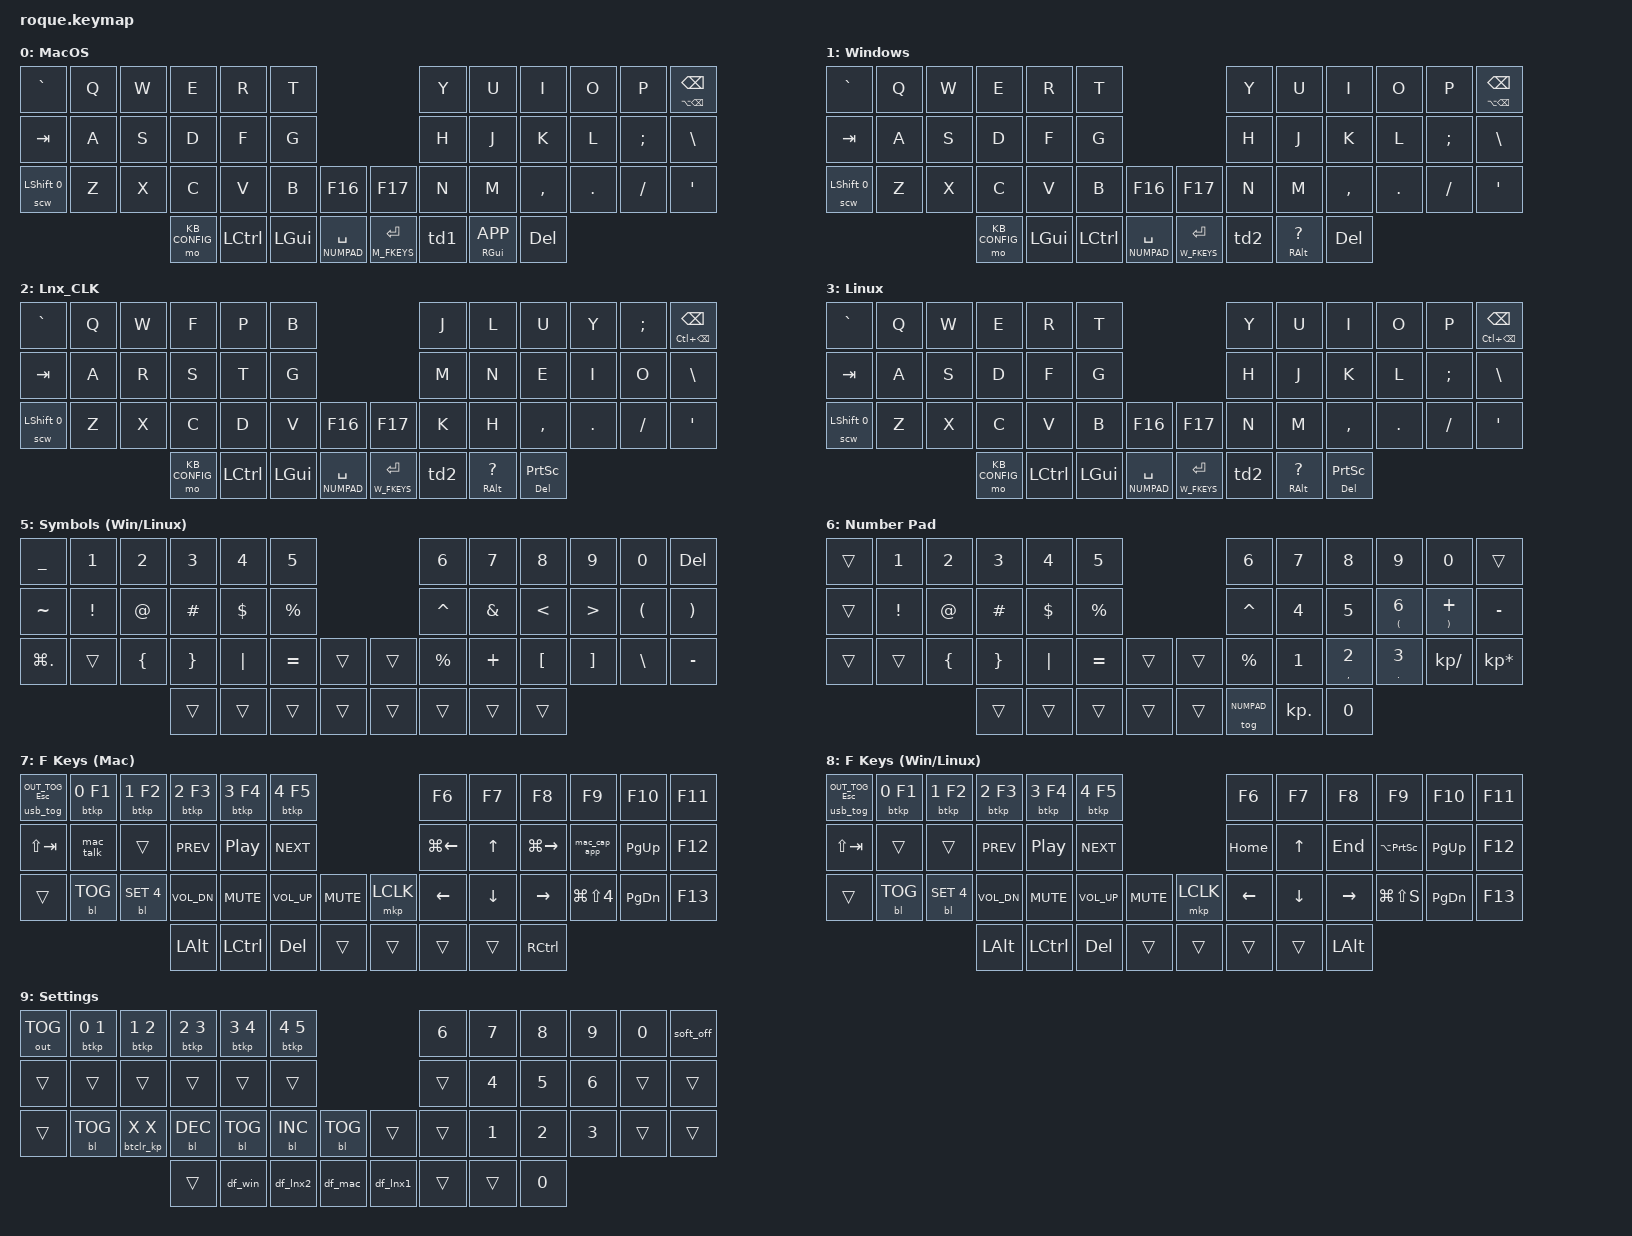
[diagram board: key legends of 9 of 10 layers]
/*
 * Copyright (c) 2023 The ZMK Contributors
 *
 * SPDX-License-Identifier: MIT
 */

#include <behaviors.dtsi>
#include <dt-bindings/zmk/keys.h>
#include <dt-bindings/zmk/bt.h>
#include <dt-bindings/zmk/outputs.h>
#include <dt-bindings/zmk/backlight.h>
#include "elpekenin/behaviors.dtsi"

#define ZMK_POINTING_DEFAULT_SCRL_VAL 100
#include <dt-bindings/zmk/pointing.h>

// Helpful macros borrowed from AndrewMSHowe
#define ___ &trans

// Layer numbers for use by the keymap & macros
#define MACOS     0
#define WINDOWS   1
#define LINUX_CLK 2
#define LINUX     3
#define M_SYMBOLS 4
#define W_SYMBOLS 5
#define NUMPAD    6
#define M_FKEYS   7
#define W_FKEYS   8
#define KB_CONFIG 9

#include "keymap_behaviors.dtsi"
#include "keymap_macros.dtsi"

/ {
    keymap {
        compatible = "zmk,keymap";

        default_layer {
            display-name = "MacOS";
            sensor-bindings = <&inc_dec_kp UP DOWN &inc_dec_kp LEFT RIGHT>;
            bindings = <
// ╭─────────────────┬─────────────┬────────────┬────────────────────┬─────────────────┬────────────╮                                         ╭───────────────┬─────────────────────┬─────────────────┬───────────────┬─────────────────┬───────────────────────╮
       &kp  GRAVE       &kp Q          &kp W        &kp E                 &kp R           &kp T   /*|                                         |*/   &kp Y          &kp U                &kp I               &kp O           &kp P             &mt LA(BSPC) BSPC
       &kp  TAB         &kp A          &kp S        &kp D                 &kp F           &kp G   /*├──────────────────╮╭─────────────────────┤*/   &kp H          &kp J                &kp K               &kp L           &kp SEMI          &kp BSLH
       &scw LSHIFT 0    &kp Z          &kp X        &kp C                 &kp V           &kp B       &kp F16             &kp F17                   &kp N          &kp M                &kp COMMA           &kp DOT         &kp FSLH           &kp SQT
/* ╰─────────────────┴─────────────┴────────────┤*/ &mo KB_CONFIG         &kp LCTRL       &kp LGUI    &lt NUMPAD SPACE    &lt M_FKEYS ENTER         &td1           &mt RGUI K_APP       &kp DEL     //├───────────────┴─────────────────┴───────────────────────╯
//                                              ╰────────────────────┴─────────────────┴────────────┴──────────────────╯╰─────────────────────┴───────────────┴─────────────────────┴─────────────────╯
            >;
        };

        windows_default_layer {
            display-name = "Windows";
            sensor-bindings = <&inc_dec_kp UP DOWN &inc_dec_kp LEFT RIGHT>;
            bindings = <
// ╭─────────────────┬─────────────┬────────────┬────────────────────┬─────────────────┬────────────╮                                         ╭───────────────┬─────────────────────┬─────────────────┬───────────────┬───────────────┬─────────────────────────╮
       &kp  GRAVE       &kp Q          &kp W        &kp E                 &kp R           &kp T   /*|                                         |*/   &kp Y          &kp U                &kp I               &kp O           &kp P             &mt LA(BSPC) BSPC
       &kp  TAB         &kp A          &kp S        &kp D                 &kp F           &kp G   /*├─────────────────╮╭──────────────────────┤*/   &kp H          &kp J                &kp K               &kp L           &kp SEMI          &kp BSLH
       &scw LSHIFT 0    &kp Z          &kp X        &kp C                 &kp V           &kp B       &kp F16             &kp F17                   &kp N          &kp M                &kp COMMA           &kp DOT         &kp FSLH          &kp APOS
/* ╰─────────────────┴─────────────┴────────────┤*/ &mo KB_CONFIG         &kp LGUI        &kp LCTRL   &lt NUMPAD SPACE    &lt W_FKEYS ENTER         &td2           &mt RALT QMARK       &kp DEL        //├───────────────┴───────────────┴─────────────────────────╯
//                                              ╰─────────────────────┴─────────────────┴───────────┴─────────────────╯╰─────────────────────┴────────────────┴─────────────────────┴─────────────────╯
            >;
        };

        Linux_CLK_default_layer {
            display-name = "Lnx_CLK";
            sensor-bindings = <&inc_dec_kp UP DOWN &inc_dec_kp LEFT RIGHT>;
            bindings = <
// ╭─────────────────┬─────────────┬────────────┬────────────────────┬─────────────────┬────────────╮                                         ╭───────────────┬─────────────────────┬─────────────────┬───────────────┬───────────────┬─────────────────────────╮
       &kp  GRAVE       &kp Q          &kp W        &kp F                 &kp P           &kp B   /*|                                         |*/   &kp J          &kp L                &kp U               &kp Y           &kp SEMI          &mt LC(BSPC) BSPC
       &kp  TAB         &kp A          &kp R        &kp S                 &kp T           &kp G   /*├──────────────────╮╭─────────────────────┤*/   &kp M          &kp N                &kp E               &kp I           &kp O             &kp BSLH
       &scw LSHIFT 0    &kp Z          &kp X        &kp C                 &kp D           &kp V       &kp F16             &kp F17                   &kp K          &kp H                &kp COMMA           &kp DOT         &kp FSLH          &kp APOS
/* ╰─────────────────┴─────────────┴────────────┤*/ &mo KB_CONFIG         &kp LCTRL       &kp LGUI    &lt NUMPAD SPACE    &lt W_FKEYS ENTER         &td2           &mt RALT QMARK       &mt DEL PSCRN //├───────────────┴───────────────┴─────────────────────────╯
//                                              ╰────────────────────┴─────────────────┴────────────┴──────────────────╯╰─────────────────────┴───────────────┴─────────────────────┴───────────────────╯
            >;
        };

        Linux_default_layer {
            display-name = "Linux";
            sensor-bindings = <&inc_dec_kp UP DOWN &inc_dec_kp LEFT RIGHT>;
            bindings = <
// ╭─────────────────┬─────────────┬────────────┬────────────────────┬─────────────────┬────────────╮                                         ╭───────────────┬─────────────────────┬─────────────────┬───────────────┬───────────────┬─────────────────────────╮
       &kp  GRAVE       &kp Q          &kp W        &kp E                 &kp R           &kp T   /*|                                         |*/   &kp Y          &kp U                &kp I               &kp O           &kp P             &mt LC(BSPC) BSPC
       &kp  TAB         &kp A          &kp S        &kp D                 &kp F           &kp G   /*├──────────────────╮╭─────────────────────┤*/   &kp H          &kp J                &kp K               &kp L           &kp SEMI          &kp BSLH
       &scw LSHIFT 0    &kp Z          &kp X        &kp C                 &kp V           &kp B       &kp F16             &kp F17                   &kp N          &kp M                &kp COMMA           &kp DOT         &kp FSLH          &kp APOS
/* ╰─────────────────┴─────────────┴────────────┤*/ &mo KB_CONFIG         &kp LCTRL       &kp LGUI    &lt NUMPAD SPACE    &lt W_FKEYS ENTER         &td2           &mt RALT QMARK       &mt DEL PSCRN  //├───────────────┴───────────────┴─────────────────────────╯
//                                              ╰────────────────────┴─────────────────┴────────────┴──────────────────╯╰─────────────────────┴───────────────┴─────────────────────┴────────────────────╯
            >;
        };

        macos_symbols_layer {
            display-name = "Symbols (Mac)";
            sensor-bindings = <&inc_dec_kp UP DOWN &inc_dec_kp LEFT RIGHT>;
            bindings = <
// ╭───────────────┬──────────────────────┬──────────────────────┬────────────────────┬───────────────┬──────────────╮                                 ╭───────────────┬───────────────┬───────────────┬───────────────┬──────────────────┬──────────────────╮
       &kp UNDER       &kp N1                   &kp N2               &kp N3              &kp N4          &kp N5    /*|                                 |*/  &kp N6         &kp N7          &kp N8          &kp N9          &kp N0               &kp DEL
       &kp ___         &kp EXCL                 &kp AT               &kp HASH            &kp DLLR        &kp PRCNT /*├─────────────╮     ╭─────────────┤*/  &kp CARET      &kp AMPERSAND   &kp STAR        &kp LPAR        &kp RPAR             &kp BSLH
       &kp LG(DOT)     ___                      &kp LEFT_BRACE       &kp RIGHT_BRACE     &kp PIPE        &kp EQUAL       ___                 ___            &kp PRCNT      &kp PLUS        &kp LBKT        &kp RBKT        &kp BACKSLASH        &kp MINUS
/* ╰───────────────┴──────────────────────┴──────────────────────┤*/ ___                 ___             ___             ___                 ___            ___            ___             ___       //├───────────────┴──────────────────┴──────────────────╯
//                                                               ╰────────────────────┴───────────────┴──────────────┴─────────────╯     ╰─────────────┴───────────────┴───────────────┴───────────────╯
            >;
        };

        windows_symbols_layer {
            display-name = "Symbols (Win/Linux)";
            sensor-bindings = <&inc_dec_kp UP DOWN &inc_dec_kp LEFT RIGHT>;
            bindings = <
// ╭───────────────┬──────────────────────┬──────────────────────┬────────────────────┬───────────────┬──────────────╮                                 ╭───────────────┬───────────────┬───────────────┬───────────────┬──────────────────┬──────────────────╮
       &kp UNDER       &kp N1                   &kp N2               &kp N3              &kp N4          &kp N5    /*|                                 |*/  &kp N6         &kp N7          &kp N8          &kp N9          &kp N0               &kp DEL
       &kp TILDE       &kp EXCL                 &kp AT               &kp HASH            &kp DLLR        &kp PRCNT /*├─────────────╮     ╭─────────────┤*/  &kp CARET      &kp AMPERSAND   &kp LT          &kp GT          &kp LPAR             &kp RPAR
       &kp LG(DOT)     ___                      &kp LEFT_BRACE       &kp RIGHT_BRACE     &kp PIPE        &kp EQUAL       ___                 ___            &kp PRCNT      &kp PLUS        &kp LBKT        &kp RBKT        &kp BACKSLASH        &kp MINUS
/* ╰───────────────┴──────────────────────┴──────────────────────┤*/ ___                 ___             ___             ___                 ___            ___            ___             ___       //├───────────────┴──────────────────┴──────────────────╯
//                                                               ╰────────────────────┴───────────────┴──────────────┴─────────────╯     ╰─────────────┴───────────────┴───────────────┴───────────────╯
            >;
        };

        numpad_layer {
            display-name = "Number Pad";
            sensor-bindings = <&mac_vol &scroll_up_down>;
            bindings = <
// ╭───────────────┬──────────────────────┬────────────────────┬───────────────────┬───────────────┬─────────────╮                                 ╭───────────────┬───────────────┬───────────────┬───────────────┬─────────────────┬──────────────────╮
       ___             &kp N1               &kp N2               &kp N3              &kp N4          &kp N5    /*|                                 |*/  &kp N6         &kp N7          &kp N8          &kp N9          &kp N0          ___ 
       ___             &kp EXCL             &kp AT               &kp HASH            &kp DLLR        &kp PRCNT /*├───────────────╮     ╭───────────┤*/  &kp CARET      &kp N4          &kp N5          &mt LPAR N6     &mt RPAR PLUS   &kp MINUS
       ___             ___                  &kp LEFT_BRACE       &kp RIGHT_BRACE     &kp PIPE        &kp EQUAL       ___                 ___            &kp PRCNT      &kp N1          &mt COMMA N2    &mt DOT N3      &kp KP_DIVIDE   &kp KP_MULTIPLY
/* ╰───────────────┴──────────────────────┴────────────────────┤*/      ___          ___             ___             ___                 ___            &tog NUMPAD    &kp KP_DOT      &kp N0    //├───────────────┴─────────────────┴──────────────────╯
//                                                             ╰───────────────────┴───────────────┴───────────────┴─────────────╯     ╰─────────────┴───────────────┴───────────────┴─────────────╯
            >;
      };


        macos_f_keys_layer {
            display-name = "F Keys (Mac)";
            sensor-bindings = <&inc_dec_kp UP DOWN &inc_dec_kp LEFT RIGHT>;
            bindings = <
// ╭──────────────────────────────┬───────────────────┬───────────────┬───────────────┬───────────────┬────────────────╮                                 ╭────────────────────┬───────────────┬───────────────────┬────────────────────┬───────────────┬───────────────╮
        &usb_tog OUT_TOG ESCAPE         &btkp 0 F1        &btkp 1 F2      &btkp 2 F3      &btkp 3 F4      &btkp 4 F5 /*|                                 |*/   &kp F6             &kp F7          &kp F8              &kp F9              &kp F10         &kp F11
        &kp LS(TAB)                     &mac_talk         ___             &kp C_PREV      &kp C_PP        &kp C_NEXT /*├─────────────╮     ╭─────────────┤*/   &kp LG(LEFT)       &kp UP          &kp LG(RIGHT)       &mac_cap_app        &kp PG_UP       &kp F12
        ___                             &bl BL_TOG        &bl BL_SET 4    &kp C_VOL_DN    &kp C_MUTE      &kp C_VOL_UP     &kp C_MUTE         &mkp LCLK        &kp LEFT           &kp DOWN        &kp RIGHT           &kp LG(LS(N4))      &kp PG_DN       &kp F13
/* ╰──────────────────────────────┴───────────────────┴───────────────┤*/ &kp LALT        &kp LCTRL       &kp DEL          ___                ___              ___                ___             &kp RCTRL     //├────────────────────┴───────────────┴───────────────╯
//                                                                    ╰───────────────┴───────────────┴───────────────┴──────────────╯     ╰─────────────┴────────────────────┴───────────────┴───────────────────╯
            >;
        };

        windows_f_keys_layer {
            display-name = "F Keys (Win/Linux)";
            sensor-bindings = <&inc_dec_kp C_VOL_UP C_VOL_DN &scroll_up_down>;
            bindings = <
// ╭────────────────────────────────┬───────────────┬───────────────┬───────────────┬───────────────┬────────────────╮                                 ╭───────────────┬───────────────┬───────────────┬───────────────┬───────────────┬───────────────╮
        &usb_tog OUT_TOG ESCAPE         &btkp 0 F1      &btkp 1 F2      &btkp 2 F3      &btkp 3 F4      &btkp 4 F5 /*|                                 |*/   &kp F6         &kp F7          &kp F8          &kp F9          &kp F10         &kp F11
        &kp LS(TAB)                     ___             ___             &kp C_PREV      &kp C_PP        &kp C_NEXT /*├─────────────╮     ╭─────────────┤*/   &kp HOME       &kp UP          &kp END         &kp LA(PSCRN)   &kp PG_UP       &kp F12
        ___                             &bl BL_TOG      &bl BL_SET 4    &kp C_VOL_DN    &kp C_MUTE      &kp C_VOL_UP    &kp C_MUTE          &mkp LCLK        &kp LEFT       &kp DOWN        &kp RIGHT       &kp LG(LS(S))   &kp PG_DN       &kp F13
/* ╰────────────────────────────────┴───────────────────────────────┤*/ &kp LALT        &kp LCTRL       &kp DEL         ___                 ___              ___            ___             &kp LALT //├───────────────┴───────────────┴───────────────╯
//                                                                  ╰───────────────┴───────────────┴────────────────┴─────────────╯     ╰─────────────┴───────────────┴───────────────┴───────────────╯
            >;

        };


      settings_layer {
            display-name = "Settings";
            sensor-bindings = <&bri_adjust &inc_dec_kp LEFT RIGHT>;
            bindings = <
// ╭───────────────┬───────────────┬───────────────┬───────────────┬───────────────┬────────────────╮                                 ╭───────────────┬───────────────┬───────────────┬───────────────┬───────────────┬───────────────╮
      &out OUT_TOG     &btkp 0 N1      &btkp 1 N2      &btkp 2 N3      &btkp 3 N4      &btkp 4 N5 /*|                                 |*/   &kp N6         &kp N7          &kp N8          &kp N9          &kp N0          &soft_off
      ___              ___             ___             ___             ___             ___        /*├──────────────╮     ╭────────────┤*/   ___            &kp N4          &kp N5          &kp N6          ___             ___
      ___              &bl BL_TOG      &btclr_kp X X   &bl BL_DEC      &bl BL_TOG      &bl BL_INC      &bl BL_TOG           ___             ___            &kp N1          &kp N2          &kp N3          ___             ___
/* ╰───────────────┴───────────────┴───────────────┤*/ ___             &df_win         &df_lnx2        &df_mac              &df_lnx1             ___            ___             &kp N0   //├───────────────┴───────────────┴───────────────╯
//                                                 ╰───────────────┴───────────────┴────────────────┴──────────────╯     ╰─────────────┴───────────────┴───────────────┴──────────────╯   
            >;
        };

        // Extra layers for ZMK Studio
        extra1 {
            status = "reserved";
        };
        extra2 {
            status = "reserved";
        };
        extra3 {
            status = "reserved";
        };

    };

};
